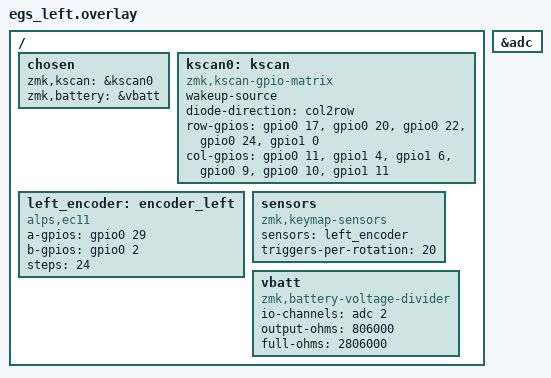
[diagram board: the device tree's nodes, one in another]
/*
 * Copyright (c) 2026 The EGS_W1 Project Contributor
 * SPDX-License-Identifier: MIT
 */

#include "egs.dtsi"

/ {
    chosen {
        zmk,kscan = &kscan0;
        zmk,battery = &vbatt;
    };

    kscan0: kscan {
        compatible = "zmk,kscan-gpio-matrix";
        wakeup-source;

        /*
         * Diode cathodes face AWAY from switches and route into ROW nets
         * Current flows: COL (driven HIGH) -> switch -> diode (anode) -> ROW (sensed HIGH).
         * This is col2row with ACTIVE_HIGH cols and PULL_DOWN rows.
         */
        diode-direction = "col2row";

        row-gpios
            = <&gpio0 17 (GPIO_ACTIVE_HIGH | GPIO_PULL_DOWN)>  /* Row0  Pin2  P0.17 */
            , <&gpio0 20 (GPIO_ACTIVE_HIGH | GPIO_PULL_DOWN)>  /* Row1  Pin3  P0.20 */
            , <&gpio0 22 (GPIO_ACTIVE_HIGH | GPIO_PULL_DOWN)>  /* Row2  Pin4  P0.22 */
            , <&gpio0 24 (GPIO_ACTIVE_HIGH | GPIO_PULL_DOWN)>  /* Row3  Pin5  P0.24 */
            , <&gpio1  0 (GPIO_ACTIVE_HIGH | GPIO_PULL_DOWN)>  /* Row4  Pin6  P1.00 */
            ;

        col-gpios
            = <&gpio0 11 GPIO_ACTIVE_HIGH>  /* Col0  Pin7   P0.11 */
            , <&gpio1  4 GPIO_ACTIVE_HIGH>  /* Col1  Pin8   P1.04 */
            , <&gpio1  6 GPIO_ACTIVE_HIGH>  /* Col2  Pin9   P1.06 */
            , <&gpio0  9 GPIO_ACTIVE_HIGH>  /* Col3  Pin10  P0.09 */
            , <&gpio0 10 GPIO_ACTIVE_HIGH>  /* Col4  Pin16  P0.10 */
            , <&gpio1 11 GPIO_ACTIVE_HIGH>  /* Col5  Pin14  P1.11 */
            ;
    };

    /* Left encoder: volume control */
    left_encoder: encoder_left {
        compatible = "alps,ec11";
        a-gpios = <&gpio0 29 (GPIO_ACTIVE_HIGH | GPIO_PULL_UP)>;  /* Pin18  P0.29 */
        b-gpios = <&gpio0  2 (GPIO_ACTIVE_HIGH | GPIO_PULL_UP)>;  /* Pin19  P0.02 */
        steps = <24>;
        status = "okay";
    };

    sensors: sensors {
        compatible = "zmk,keymap-sensors";
        sensors = <&left_encoder>;
        triggers-per-rotation = <20>;
    };

    /*
     * Battery voltage divider on P0.04 (AIN2).
     * The nice!nano v2 / compatible clones use a 2MΩ + 806kΩ divider,
     * giving a full-scale output of ~806/(2000+806) = ~0.287 of VBAT.
     * ZMK's voltage divider driver computes: VBAT = Vmeasured * (R1+R2) / R2
     */
    vbatt: vbatt {
        compatible = "zmk,battery-voltage-divider";
        io-channels = <&adc 2>;   /* AIN2 = P0.04 */
        output-ohms = <806000>;
        full-ohms = <2806000>;
    };
};

/* Enable the ADC peripheral */
&adc {
    status = "okay";
};
